# GPTIMER5_DSP register map
Vendor: Texas Instruments
Peripheral module from a debugger description file (folder omap4430).
Registers are 32-bit, access per field, reset 0x0 unless marked. A register's access mark holds for its fields unless they carry their own. Offsets are as the file gives them; lines under a group give offsets from that group; [hi:lo] are bit positions; {n}, {i} and the like mark numbered series; 'fields as' and 'values as' point back to an identical list; <NAME> marks a mode.

## GPTIMER5_DSP
0x00 GPT_TIDR ro reset not defined — This read-only register contains the revision number of the module. A write to this register has no effect. This register is used by software to track features, bugs, and compatibility.
  [31:0] REVISION — IP Revision
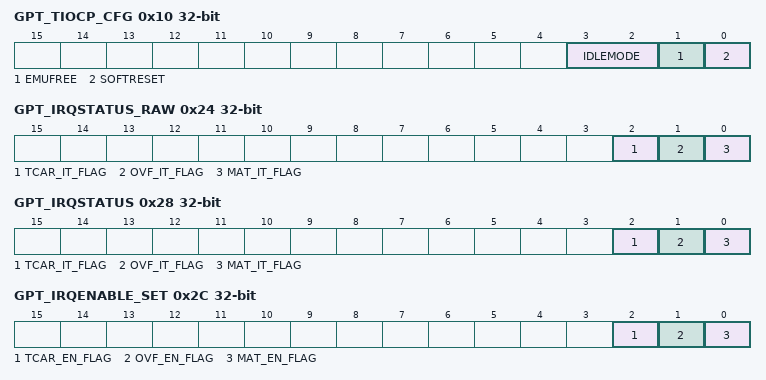
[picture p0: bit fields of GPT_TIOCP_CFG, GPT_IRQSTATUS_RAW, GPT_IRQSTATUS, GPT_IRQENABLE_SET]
0x10 GPT_TIOCP_CFG — This register controls the various parameters of the L4 interface.
  [3:2] IDLEMODE rw — Power management, req/ack control
    0=Force-idle mode: local target idle state follows (acknowledges) the system idle requests unconditionally, that is, regardless of the IP module internal requirements. Back-up mode, for debug only.; 1=No-idle mode: local target never enters idle state. Back-up mode, for debug only.; 2=Smart-idle mode: local target idle state eventually follows (acknowledges) the system idle requests, depending on the IP module internal requirements. IP module should not generate (IRQ- or DMA-request-related) wake-up events.; 3=Smart-idle wake-up-capable mode: local target idle state eventually follows (acknowledges) the system idle requests, depending on the IP module internal requirements. IP module may generate (IRQ- or DMA-request-related) wake-up events when in idle state. Mode is only relevant if the appropriate IP moduleswake-up output(s) is (are) implemented.
  [1] EMUFREE rw — Emulation mode
    0=The timer is frozen in emulation mode (PINSUSPENDN signal active); 1=The timer runs free, regardless of PINSUSPENDN value
  [0] SOFTRESET rw — Software reset
    0=Read 0: reset done, no pending action Write 0: No action; 1=Read 1: initiate software reset Write 1: Reset ongoing
0x24 GPT_IRQSTATUS_RAW — Component interrupt-request status. Check the corresponding secondary status register. Raw status is set even if event is not enabled. Write 1 to set the (raw) status, mostly for debug.
  [2] TCAR_IT_FLAG rw — IRQ status for CaptureRead 0: No event pending Write 0: No action Read 1: IRQ event pending Write 1: Trigger IRQ event by software.
  [1] OVF_IT_FLAG rw — IRQ status for OverflowRead 0: No event pending Write 0: No action Read 1: IRQ event pending Write 1: Trigger IRQ event by software.
  [0] MAT_IT_FLAG rw — IRQ status for MatchRead 0: No event pending Write 0: No action Read 1: IRQ event pending Write 1: Trigger IRQ event by software
0x28 GPT_IRQSTATUS — Component interrupt-request status. Check the corresponding secondary status register. Enabled status is not set unless event is enabled. Write 1 to clear the status after interrupt has been serviced (raw status gets cleared, that is, even if not enabled).
  [2] TCAR_IT_FLAG rw — IRQ status for captureRead 0: No event pending Write 0: No action Read 1: IRQ event pending Write 1: Clear any pending event.
  [1] OVF_IT_FLAG rw — IRQ status for OverflowRead 0: No event pending Write 0: No action Read 1: IRQ event pending Write 1: Clear any pending event.
  [0] MAT_IT_FLAG rw — IRQ status for MatchRead 0: No event pending Write 0: No action Read 1: IRQ event pending Write 1: Clear any pending event.
0x2C GPT_IRQENABLE_SET — Component interrupt-request enable. Write 1 to set (enable interrupt). Readout equal to corresponding _CLR register.
  [2] TCAR_EN_FLAG rw — IRQ enable for CompareRead 0: IRQ event is disabled.Write 0: No action Read 1: IRQ event is enabled Write 1: Set IRQ enable.
  [1] OVF_EN_FLAG rw — IRQ enable for OverflowRead 0: IRQ event is disabled.Write 0: No action Read 1: IRQ event is enabled.Write 1: Set IRQ enable.
  [0] MAT_EN_FLAG rw — IRQ enable for MatchRead 0: IRQ event is disabled.Write 0: No action Read 1: IRQ event is enabled.Write 1: Set IRQ enable.
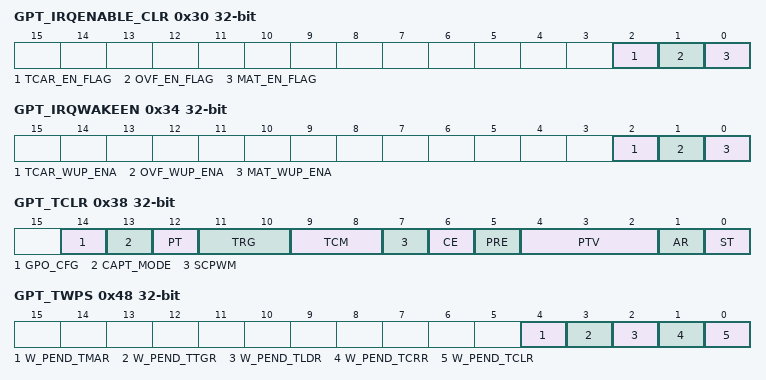
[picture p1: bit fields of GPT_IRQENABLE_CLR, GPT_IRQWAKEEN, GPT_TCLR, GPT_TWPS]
0x30 GPT_IRQENABLE_CLR — Component interrupt-request enable. Write 1 to clear (disable interrupt). Readout equal to corresponding _SET register.
  [2] TCAR_EN_FLAG rw — IRQ enable for CompareRead 0: IRQ event is disabled.Write 0: No action Read 1: IRQ event is enabled.Write 1: Clear IRQ enable.
  [1] OVF_EN_FLAG rw — IRQ enable for OverflowRead 0: IRQ event is disabled.Write 0: No action Read 1: IRQ event is enabled.Write 1: Clear IRQ enable.
  [0] MAT_EN_FLAG rw — IRQ enable for MatchRead 0: IRQ event is disabled.Write 0: No action Read 1: IRQ event is enabled.Write 1: Clear IRQ enable.
0x34 GPT_IRQWAKEEN — Wake-up-enabled events taking place when module is idle should generate an asynchronous wake-up.
  [all] fields
    0=Wake-up disabled; 1=Wake-up enabled
  [2] TCAR_WUP_ENA rw — Wake-up generation for Compare
  [1] OVF_WUP_ENA rw — Wake-up generation for Overflow
  [0] MAT_WUP_ENA rw — Wake-up generation for Match
0x38 GPT_TCLR — This register controls optional features specific to the timer functionality.
  [14] GPO_CFG rw — General-purpose output - this register directly drives the GPTi_PORGPOCFG output pin. For specific use of the GPO_CFG bit, see, .
    0=GPTi_PORGPOCFG drives 0; 1=GPTi_PORGPOCFG drives 1
  [13] CAPT_MODE rw — Capture mode select bit (first/second)
    0=Single capture: Capture the first enabled capture event in TCAR1; 1=Capture on second event: Capture the second enabled capture event in TCAR2
  [12] PT rw — Pulse or toggle mode on GPTi_PWM_out output pin
    0=Pulse modulation; 1=Toggle modulation
  [11:10] TRG rw — Trigger output mode on GPTi_PWM_out output pin
    0=No trigger; 1=Trigger on overflow; 2=Trigger on overflow and match
  [9:8] TCM rw — Transition capture mode on GPTi_EVENT_CAPTURE input pin (When the TCM field passed from (00) to any other combination, the TCAR_IT_FLAG and the edge detection logic are cleared.)
    0=No capture; 1=Capture on rising edges of GPTi_EVENT_CAPTURE pin; 2=Capture on falling edges of GPTi_EVENT_CAPTURE pin; 3=Capture on both edges of GPTi_EVENT_CAPTURE pin
  [7] SCPWM rw — Pulse width modulation output pin default settingThis bit must be set or clear while the timer is stopped or the trigger is off.
    0=Clear the GPTi_PWM_out output pin and select positive pulse for pulse mode; 1=Set the GPTi_PWM_out output pin and select negative pulse for pulse mode
  [6] CE rw — Compare enable
    0=Compare mode is disable; 1=Compare mode is enable
  [5] PRE rw — Prescaler enable
    0=The TIMER clock input pin clocks the counter; 1=The divided input pin clocks the counter
  [4:2] PTV rw — Prescale clock timer valueThe timer counter is prescaled with the value 2. Example: PTV = 3, counter increases value (if started) after 16 functional clock periods.
  [1] AR rw — Autoreload mode
    0=One shot timer; 1=Autoreload timer
  [0] ST rw — Start/stop timer control
    0=Stop timer: Only the counter is frozen. If one-shot mode selected (AR =0), this bit is automatically reset by internal logic when the counter is overflowed.; 1=Start timer
0x3C GPT_TCRR rw — This register holds the value of the internal counter.
  [31:0] TIMER_COUNTER — Value of TIMER counter
0x40 GPT_TLDR rw — This register holds the timer load value.
  [31:0] LOAD_VALUE — Timer counter value loaded on overflow in autoreload mode or onGPT_TTGR write access. LOAD_VALUE must be different than the timer overflow value (0xFFFF FFFF).
0x44 GPT_TTGR access not given reset 0xFFFFFFFF — The read value of this register is always 0xFFFF FFFF.
  [31:0] TTGR_VALUE — Writing to the TTGR register causes theGPT_TCRR to be loaded from GPT_TLDR and the prescaler counter to be cleared. Reload is done regardless of the AR field value of the GPT_TCLR register. (access RW Rreturns1s)
0x48 GPT_TWPS ro — This register contains the write posting bits for all writable functional registers.
  [4] W_PEND_TMAR — When equal to 1, a write is pending to theGPT_TMAR register.
  [3] W_PEND_TTGR — When equal to 1, a write is pending to theGPT_TTGR register.
  [2] W_PEND_TLDR — When equal to 1, a write is pending to theGPT_TLDR register.
  [1] W_PEND_TCRR — When equal to 1, a write is pending to theGPT_TCRR register.
  [0] W_PEND_TCLR — When equal to 1, a write is pending to theGPT_TCLR register.
0x4C GPT_TMAR rw — The compare logic consists of a 32-bit-wide, read/write data TMAR register and logic to compare counter.
  [31:0] COMPARE_VALUE — Value to be compared to the timer counter
0x50 GPT_TCAR1 ro — This register holds the first captured value of the counter register.
  [31:0] CAPTURE_VALUE1 — First timer counter value captured on an external event trigger
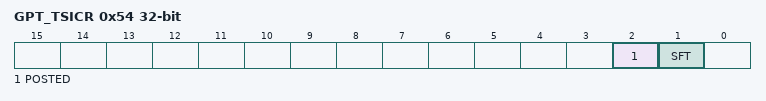
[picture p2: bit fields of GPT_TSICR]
0x54 GPT_TSICR (reset mask 0xFFFFFFFB) — Timer synchronous interface control register
  [2] POSTED rw — Posted mode selection
    0=Posted mode inactive: Delay the command accept output signal; 1=Posted mode active
  [1] SFT rw — This bit resets all the functional part of the module.
    0=Software reset is disabled; 1=Software reset is enabled
0x58 GPT_TCAR2 ro — This register holds the second captured value of the counter register.
  [31:0] CAPTURE_VALUE2 — Second timer counter value captured on an external event trigger
